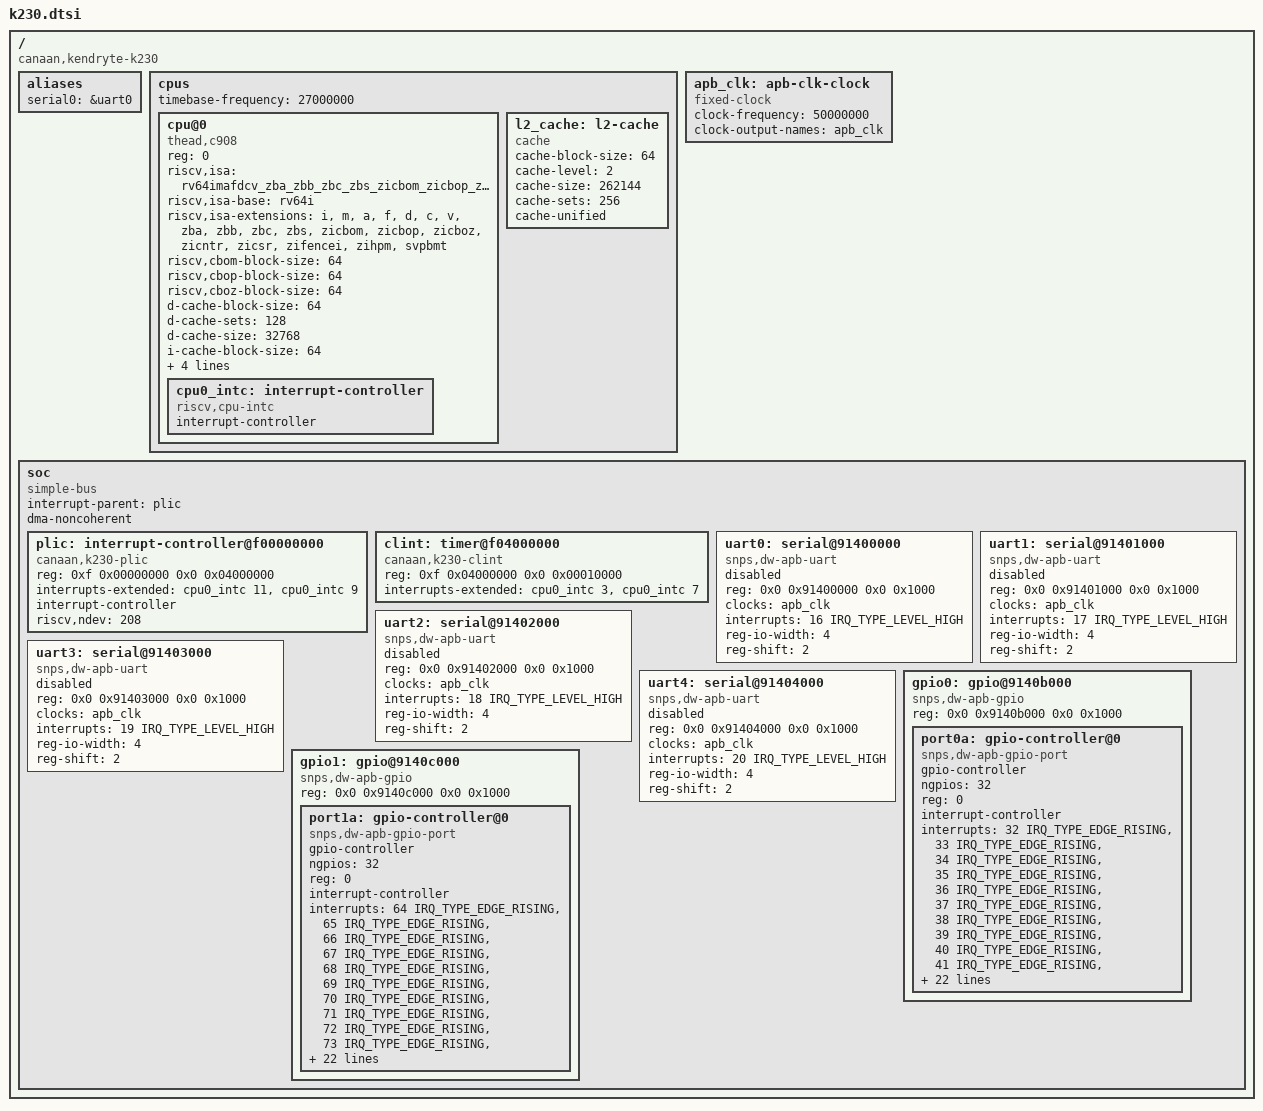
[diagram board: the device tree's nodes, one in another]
// SPDX-License-Identifier: GPL-2.0 OR MIT
/*
 * Copyright (C) 2024 Yangyu Chen <cyy@cyyself.name>
 */

#include <dt-bindings/interrupt-controller/irq.h>

/dts-v1/;
/ {
	#address-cells = <2>;
	#size-cells = <2>;
	compatible = "canaan,kendryte-k230";

	aliases {
		serial0 = &uart0;
	};

	cpus {
		#address-cells = <1>;
		#size-cells = <0>;
		timebase-frequency = <27000000>;

		cpu@0 {
			compatible = "thead,c908", "riscv";
			device_type = "cpu";
			reg = <0>;
			riscv,isa = "rv64imafdcv_zba_zbb_zbc_zbs_zicbom_zicbop_zicboz_svpbmt";
			riscv,isa-base = "rv64i";
			riscv,isa-extensions = "i", "m", "a", "f", "d", "c", "v", "zba", "zbb",
					       "zbc", "zbs", "zicbom", "zicbop", "zicboz",
					       "zicntr", "zicsr", "zifencei", "zihpm", "svpbmt";
			riscv,cbom-block-size = <64>;
			riscv,cbop-block-size = <64>;
			riscv,cboz-block-size = <64>;
			d-cache-block-size = <64>;
			d-cache-sets = <128>;
			d-cache-size = <32768>;
			i-cache-block-size = <64>;
			i-cache-sets = <128>;
			i-cache-size = <32768>;
			next-level-cache = <&l2_cache>;
			mmu-type = "riscv,sv39";

			cpu0_intc: interrupt-controller {
				compatible = "riscv,cpu-intc";
				interrupt-controller;
				#interrupt-cells = <1>;
			};
		};

		l2_cache: l2-cache {
			compatible = "cache";
			cache-block-size = <64>;
			cache-level = <2>;
			cache-size = <262144>;
			cache-sets = <256>;
			cache-unified;
		};
	};

	apb_clk: apb-clk-clock {
		compatible = "fixed-clock";
		clock-frequency = <50000000>;
		clock-output-names = "apb_clk";
		#clock-cells = <0>;
	};

	soc {
		compatible = "simple-bus";
		interrupt-parent = <&plic>;
		#address-cells = <2>;
		#size-cells = <2>;
		dma-noncoherent;
		ranges;

		plic: interrupt-controller@f00000000 {
			compatible = "canaan,k230-plic" ,"thead,c900-plic";
			reg = <0xf 0x00000000 0x0 0x04000000>;
			interrupts-extended = <&cpu0_intc 11>, <&cpu0_intc 9>;
			interrupt-controller;
			#address-cells = <0>;
			#interrupt-cells = <2>;
			riscv,ndev = <208>;
		};

		clint: timer@f04000000 {
			compatible = "canaan,k230-clint", "thead,c900-clint";
			reg = <0xf 0x04000000 0x0 0x00010000>;
			interrupts-extended = <&cpu0_intc 3>, <&cpu0_intc 7>;
		};

		uart0: serial@91400000 {
			compatible = "snps,dw-apb-uart";
			reg = <0x0 0x91400000 0x0 0x1000>;
			clocks = <&apb_clk>;
			interrupts = <16 IRQ_TYPE_LEVEL_HIGH>;
			reg-io-width = <4>;
			reg-shift = <2>;
			status = "disabled";
		};

		uart1: serial@91401000 {
			compatible = "snps,dw-apb-uart";
			reg = <0x0 0x91401000 0x0 0x1000>;
			clocks = <&apb_clk>;
			interrupts = <17 IRQ_TYPE_LEVEL_HIGH>;
			reg-io-width = <4>;
			reg-shift = <2>;
			status = "disabled";
		};

		uart2: serial@91402000 {
			compatible = "snps,dw-apb-uart";
			reg = <0x0 0x91402000 0x0 0x1000>;
			clocks = <&apb_clk>;
			interrupts = <18 IRQ_TYPE_LEVEL_HIGH>;
			reg-io-width = <4>;
			reg-shift = <2>;
			status = "disabled";
		};

		uart3: serial@91403000 {
			compatible = "snps,dw-apb-uart";
			reg = <0x0 0x91403000 0x0 0x1000>;
			clocks = <&apb_clk>;
			interrupts = <19 IRQ_TYPE_LEVEL_HIGH>;
			reg-io-width = <4>;
			reg-shift = <2>;
			status = "disabled";
		};

		uart4: serial@91404000 {
			compatible = "snps,dw-apb-uart";
			reg = <0x0 0x91404000 0x0 0x1000>;
			clocks = <&apb_clk>;
			interrupts = <20 IRQ_TYPE_LEVEL_HIGH>;
			reg-io-width = <4>;
			reg-shift = <2>;
			status = "disabled";
		};

		gpio0: gpio@9140b000 {
			compatible = "snps,dw-apb-gpio";
			reg = <0x0 0x9140b000 0x0 0x1000>;
			#address-cells = <1>;
			#size-cells = <0>;

			port0a: gpio-controller@0 {
				compatible = "snps,dw-apb-gpio-port";
				gpio-controller;
				#gpio-cells = <2>;
				ngpios = <32>;
				reg = <0>;
				interrupt-controller;
				#interrupt-cells = <2>;
				interrupts = <32 IRQ_TYPE_EDGE_RISING>,
					     <33 IRQ_TYPE_EDGE_RISING>,
					     <34 IRQ_TYPE_EDGE_RISING>,
					     <35 IRQ_TYPE_EDGE_RISING>,
					     <36 IRQ_TYPE_EDGE_RISING>,
					     <37 IRQ_TYPE_EDGE_RISING>,
					     <38 IRQ_TYPE_EDGE_RISING>,
					     <39 IRQ_TYPE_EDGE_RISING>,
					     <40 IRQ_TYPE_EDGE_RISING>,
					     <41 IRQ_TYPE_EDGE_RISING>,
					     <42 IRQ_TYPE_EDGE_RISING>,
					     <43 IRQ_TYPE_EDGE_RISING>,
					     <44 IRQ_TYPE_EDGE_RISING>,
					     <45 IRQ_TYPE_EDGE_RISING>,
					     <46 IRQ_TYPE_EDGE_RISING>,
					     <47 IRQ_TYPE_EDGE_RISING>,
					     <48 IRQ_TYPE_EDGE_RISING>,
					     <49 IRQ_TYPE_EDGE_RISING>,
					     <50 IRQ_TYPE_EDGE_RISING>,
					     <51 IRQ_TYPE_EDGE_RISING>,
					     <52 IRQ_TYPE_EDGE_RISING>,
					     <53 IRQ_TYPE_EDGE_RISING>,
					     <54 IRQ_TYPE_EDGE_RISING>,
					     <55 IRQ_TYPE_EDGE_RISING>,
					     <56 IRQ_TYPE_EDGE_RISING>,
					     <57 IRQ_TYPE_EDGE_RISING>,
					     <58 IRQ_TYPE_EDGE_RISING>,
					     <59 IRQ_TYPE_EDGE_RISING>,
					     <60 IRQ_TYPE_EDGE_RISING>,
					     <61 IRQ_TYPE_EDGE_RISING>,
					     <62 IRQ_TYPE_EDGE_RISING>,
					     <63 IRQ_TYPE_EDGE_RISING>;
			};
		};

		gpio1: gpio@9140c000 {
			compatible = "snps,dw-apb-gpio";
			reg = <0x0 0x9140c000  0x0 0x1000>;
			#address-cells = <1>;
			#size-cells = <0>;
			port1a: gpio-controller@0 {
				compatible = "snps,dw-apb-gpio-port";
				gpio-controller;
				#gpio-cells = <2>;
				ngpios = <32>;
				reg = <0>;
				interrupt-controller;
				#interrupt-cells = <2>;
				interrupts = <64 IRQ_TYPE_EDGE_RISING>,
					     <65 IRQ_TYPE_EDGE_RISING>,
					     <66 IRQ_TYPE_EDGE_RISING>,
					     <67 IRQ_TYPE_EDGE_RISING>,
					     <68 IRQ_TYPE_EDGE_RISING>,
					     <69 IRQ_TYPE_EDGE_RISING>,
					     <70 IRQ_TYPE_EDGE_RISING>,
					     <71 IRQ_TYPE_EDGE_RISING>,
					     <72 IRQ_TYPE_EDGE_RISING>,
					     <73 IRQ_TYPE_EDGE_RISING>,
					     <74 IRQ_TYPE_EDGE_RISING>,
					     <75 IRQ_TYPE_EDGE_RISING>,
					     <76 IRQ_TYPE_EDGE_RISING>,
					     <77 IRQ_TYPE_EDGE_RISING>,
					     <78 IRQ_TYPE_EDGE_RISING>,
					     <79 IRQ_TYPE_EDGE_RISING>,
					     <80 IRQ_TYPE_EDGE_RISING>,
					     <81 IRQ_TYPE_EDGE_RISING>,
					     <82 IRQ_TYPE_EDGE_RISING>,
					     <83 IRQ_TYPE_EDGE_RISING>,
					     <84 IRQ_TYPE_EDGE_RISING>,
					     <85 IRQ_TYPE_EDGE_RISING>,
					     <86 IRQ_TYPE_EDGE_RISING>,
					     <87 IRQ_TYPE_EDGE_RISING>,
					     <88 IRQ_TYPE_EDGE_RISING>,
					     <89 IRQ_TYPE_EDGE_RISING>,
					     <90 IRQ_TYPE_EDGE_RISING>,
					     <91 IRQ_TYPE_EDGE_RISING>,
					     <92 IRQ_TYPE_EDGE_RISING>,
					     <93 IRQ_TYPE_EDGE_RISING>,
					     <94 IRQ_TYPE_EDGE_RISING>,
					     <95 IRQ_TYPE_EDGE_RISING>;
			};
		};
	};
};
